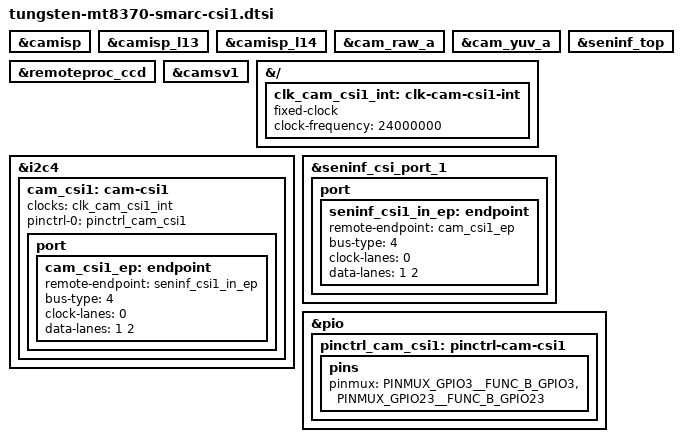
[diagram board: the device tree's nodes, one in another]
// SPDX-License-Identifier: (GPL-2.0+ OR MIT)
/*
 * Copyright (C) 2026 Ezurio LLC
 */

#include <dt-bindings/gpio/gpio.h>
#include <dt-bindings/pinctrl/mediatek,mt8188-pinfunc.h>

&camisp { status = "okay"; };
&camisp_l13 { status = "okay"; };
&camisp_l14 { status = "okay"; };
&cam_raw_a { status = "okay"; };
&cam_yuv_a { status = "okay"; };
&remoteproc_ccd { status = "okay"; };
&seninf_top { status = "okay"; };
&camsv1 { status = "okay"; };

&{/} {
	clk_cam_csi1_int: clk-cam-csi1-int {
		compatible = "fixed-clock";
		#clock-cells = <0>;
		clock-frequency = <24000000>;
	};
};

&i2c4 {
	status = "okay";

	#address-cells = <1>;
	#size-cells = <0>;

	cam_csi1: cam-csi1 {
		clocks = <&clk_cam_csi1_int>;
		clock-names = "xclk";

		pinctrl-names = "default";
		pinctrl-0 = <&pinctrl_cam_csi1>;

		port {
			cam_csi1_ep: endpoint {
				remote-endpoint = <&seninf_csi1_in_ep>;
				bus-type = <4>;
				clock-lanes = <0>;
				data-lanes = <1 2>;
			};
		};
	};
};

&seninf_csi_port_1 {
	status = "okay";

	port {
		seninf_csi1_in_ep: endpoint {
			remote-endpoint = <&cam_csi1_ep>;
			bus-type = <4>;
			clock-lanes = <0>;
			data-lanes = <1 2>;
		};
	};
};

&pio {
	pinctrl_cam_csi1: pinctrl-cam-csi1 {
		pins {
			pinmux = <PINMUX_GPIO3__FUNC_B_GPIO3>,
				 <PINMUX_GPIO23__FUNC_B_GPIO23>;
		};
	};
};
